# PIC16LF1578 register map
Vendor: Microchip
Architecture 16Exxx. Special function registers and configuration words.
Registers are 8-bit, read-write, reset 0x0 unless marked. A register's access mark holds for its fields unless they carry their own. Addresses are absolute, and some are shared; only a register's first bit layout is shown; lines under a group give offsets from that group; [hi:lo] are bit positions; {n}, {i} and the like mark numbered series; 'fields as' and 'values as' point back to an identical list; <NAME> marks a mode.

## Further device data
pins=1: Vdd; 2: RA5/IOCA5/CLKIN; 3: RA4/AN3/IOCA4/CLKOUT; 4: RA3/IOCA3/MCLR_n/ICDMCLR_n/Vpp; 5: RC5/IOCC5; 6: RC4/IOCC4; 7: RC3/AN7/C1IN3-/C2IN3-/IOCC3; 8: RC6/AN8/IOCC6; 9: RC7/AN9/IOCC7; 10: RB7/IOCB7; 11: RB6/IOCB6; 12: RB5/AN11/IOCB5; 13: RB4/AN10/IOCB4; 14: RC2/AN6/C1IN2-/C2IN2-/IOCC2; 15: RC1/AN5/C1IN1-/C2IN1-/IOCC1; 16: RC0/AN4/C2IN+/IOCC0; 17: RA2/AN2/IOCA2; 18: RA1/AN1/VREF+/C1IN0-/C2IN0-/IOCA1/ICSPCLK/ICDCLK; 19: RA0/AN0/C1IN+/DACOUT/IOCA0/ICSPDAT/ICDDAT; 20: Vss

## A4
0x691 CWG1DBR reset not defined — (power-on value --xxxxxx)
  [5:0] CWG1DBR
0x692 CWG1DBF reset not defined — (power-on value --xxxxxx)
  [5:0] CWG1DBF
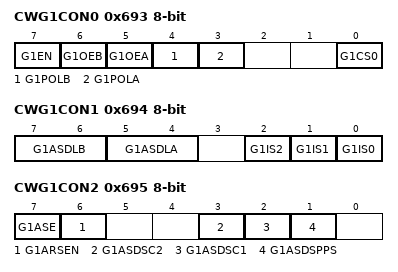
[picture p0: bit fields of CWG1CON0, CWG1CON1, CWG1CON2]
0x693 CWG1CON0 reset not defined — Configurable logic cell control (power-on value 00000--x)
  [7] G1EN, [6] G1OEB, [5] G1OEA, [4] G1POLB, [3] G1POLA, [0] G1CS0
0x694 CWG1CON1 reset not defined — (power-on value xxxx-xxx)
  [7:6] G1ASDLB, [5:4] G1ASDLA, [2] G1IS2, [1] G1IS1, [0] G1IS0
0x695 CWG1CON2 reset not defined — (power-on value xx--xxx-)
  [7] G1ASE, [6] G1ARSEN, [3] G1ASDSC2, [2] G1ASDSC1, [1] G1ASDSPPS

## pwm
{0xD81+0x10*i} PWM{i}PHL reset not defined (i=1..4) — 8-bit period timer (power-on value xxxxxxxx)
  [7:0] PH
{0xD82+0x10*i} PWM{i}PHH reset not defined (i=1..4) — (power-on value xxxxxxxx)
  [7:0] PH
{0xD83+0x10*i} PWM{i}DCL reset not defined (i=1..4) — (power-on value xxxxxxxx)
  [7:0] DC
{0xD84+0x10*i} PWM{i}DCH reset not defined (i=1..4) — (power-on value xxxxxxxx)
  [7:0] DC
{0xD85+0x10*i} PWM{i}PRL reset not defined (i=1..4) — (power-on value xxxxxxxx)
  [7:0] PR
{0xD86+0x10*i} PWM{i}PRH reset not defined (i=1..4) — (power-on value xxxxxxxx)
  [7:0] PR
{0xD87+0x10*i} PWM{i}OFL reset not defined (i=1..4) — (power-on value xxxxxxxx)
  [7:0] OF
{0xD88+0x10*i} PWM{i}OFH reset not defined (i=1..4) — (power-on value xxxxxxxx)
  [7:0] OF
{0xD89+0x10*i} PWM{i}TMRL (i=1..4)
  [7:0] TMR
{0xD8A+0x10*i} PWM{i}TMRH (i=1..4)
  [7:0] TMR
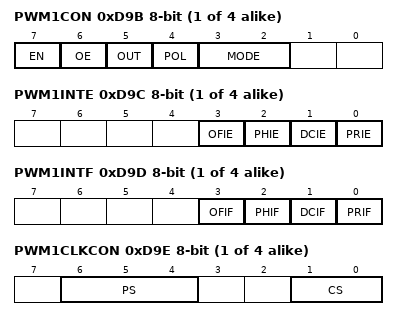
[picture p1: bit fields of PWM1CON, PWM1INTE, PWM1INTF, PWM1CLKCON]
{0xD8B+0x10*i} PWM{i}CON (i=1..4)
  [7] EN, [6] OE, [5] OUT ro, [4] POL, [3:2] MODE
{0xD8C+0x10*i} PWM{i}INTE (i=1..4)
  [3] OFIE, [2] PHIE, [1] DCIE, [0] PRIE
{0xD8D+0x10*i} PWM{i}INTF (i=1..4)
  [3] OFIF — (can only be cleared)
  [2] PHIF — (can only be cleared)
  [1] DCIF — (can only be cleared)
  [0] PRIF — (can only be cleared)
{0xD8E+0x10*i} PWM{i}CLKCON (i=1..4)
  [6:4] PS, [1:0] CS
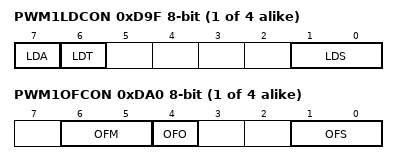
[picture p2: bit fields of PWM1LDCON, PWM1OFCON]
{0xD8F+0x10*i} PWM{i}LDCON (i=1..4)
  [7] LDA, [6] LDT, [1:0] LDS
{0xD90+0x10*i} PWM{i}OFCON (i=1..4)
  [6:5] OFM, [4] OFO, [1:0] OFS

## CONFIG — Configuration words, addresses in ProgramSpace
0x8007 CONFIG1 14-bit reset 0x3FFF
  [11] CLKOUTEN — Clock Out Enable
    1=OFF (CLKOUT function is disabled. I/O or oscillator function on the CLKOUT pin); 0=ON (CLKOUT function is enabled on the CLKOUT pin)
  [10:9] BOREN — Brown-out Reset Enable
    3=ON (Brown-out Reset enabled); 2=NSLEEP (Brown-out Reset enabled while running and disabled in Sleep); 1=SBODEN (Brown-out Reset controlled by the SBOREN bit in the BORCON register); 0=OFF (Brown-out Reset disabled)
  [7] CP — Flash Program Memory Code Protection
    1=OFF (Program memory code protection is disabled); 0=ON (Program memory code protection is enabled)
  [6] MCLRE — MCLR Pin Function Select
    1=ON (MCLR/VPP pin function is MCLR); 0=OFF (MCLR/VPP pin function is digital input)
  [5] PWRTE — Power-up Timer Enable
    1=OFF (PWRT disabled); 0=ON (PWRT enabled)
  [4:3] WDTE — Watchdog Timer Enable
    3=ON (WDT enabled); 2=NSLEEP (WDT enabled while running and disabled in Sleep); 1=SWDTEN (WDT controlled by the SWDTEN bit in the WDTCON register); 0=OFF (WDT disabled)
  [1:0] FOSC — Oscillator Selection Bits
    3=ECH (ECH, External Clock, High Power Mode (4-32 MHz); device clock supplied to CLKIN pin); 2=ECM (ECM, External Clock, Medium Power Mode (0.5-4 MHz); device clock supplied to CLKIN pin); 1=ECL (ECL, External Clock, Low Power Mode (0-0.5 MHz); device clock supplied to CLKIN pin); 0=INTOSC (INTOSC oscillator; I/O function on CLKIN pin)
0x8008 CONFIG2 14-bit reset 0x3FFF
  [13] LVP — Low-Voltage Programming Enable
    1=ON (Low-voltage programming enabled); 0=OFF (High-voltage on MCLR/VPP must be used for programming)
  [12] DEBUG — In-Circuit Debugger Mode
    1=OFF (In-Circuit Debugger disabled, ICSPCLK and ICSPDAT are general purpose I/O pins); 0=ON (In-Circuit Debugger enabled, ICSPCLK and ICSPDAT are dedicated to the debugger)
  [11] LPBOREN — Low Power Brown-out Reset enable bit
    1=OFF (LPBOR is disabled); 0=ON (LPBOR is enabled)
  [10] BORV — Brown-out Reset Voltage Selection
    1=LO (Brown-out Reset Voltage (Vbor), low trip point selected.); 0=HI (Brown-out Reset Voltage (Vbor), high trip point selected.)
  [9] STVREN — Stack Overflow/Underflow Reset Enable
    1=ON (Stack Overflow or Underflow will cause a Reset); 0=OFF (Stack Overflow or Underflow will not cause a Reset)
  [8] PLLEN — PLL Enable
    1=ON (4x PLL enabled); 0=OFF (4x PLL disabled)
  [2] PPS1WAY — PPSLOCK bit One-Way Set Enable bit
    1=ON (PPSLOCKED Bit Can Be Cleared & Set Once); 0=OFF (PPSLOCKED Bit Can Be Cleared & Set Repeatedly)
  [1:0] WRT — Flash Memory Self-Write Protection
    3=OFF (Write protection off); 2=BOOT (000h to 1FFh write protected, 200h to FFFh may be modified by EECON control); 1=HALF (000h to 7FFh write protected, 800h to FFFh may be modified by EECON control); 0=ALL (000h to FFFh write protected, no addresses may be modified by EECON control)
